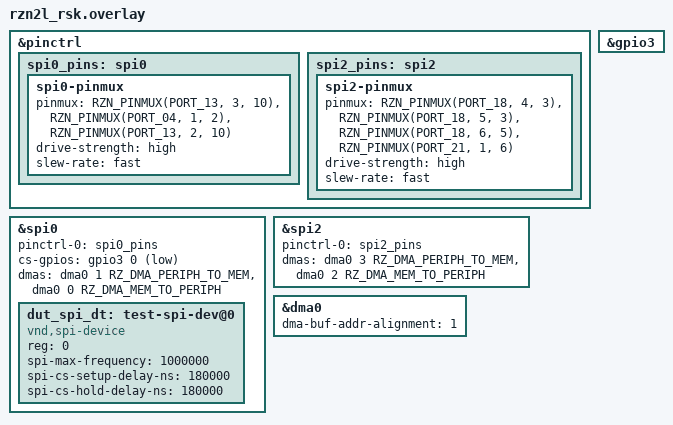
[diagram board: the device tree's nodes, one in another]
/*
 * Copyright (c) 2025 Renesas Electronics Corporation
 * SPDX-License-Identifier: Apache-2.0
 */

&pinctrl {
	/omit-if-no-ref/ spi0_pins: spi0 {
		spi0-pinmux {
			pinmux = <RZN_PINMUX(PORT_13, 3, 10)>, /* CK0 */
				 <RZN_PINMUX(PORT_04, 1, 2)>, /* MOSI0 */
				 <RZN_PINMUX(PORT_13, 2, 10)>; /* MISO0 */
			drive-strength = "high";
			slew-rate = "fast";
		};
	};

	/omit-if-no-ref/ spi2_pins: spi2 {
		spi2-pinmux {
			pinmux = <RZN_PINMUX(PORT_18, 4, 3)>, /* CK2 */
				 <RZN_PINMUX(PORT_18, 5, 3)>, /* MOSI2 */
				 <RZN_PINMUX(PORT_18, 6, 5)>, /* MISO2 */
				 <RZN_PINMUX(PORT_21, 1, 6)>; /* SSL20 */
			drive-strength = "high";
			slew-rate = "fast";
		};
	};
};

&gpio3 {
	status = "okay";
};

&spi0 {
	status = "okay";
	pinctrl-0 = <&spi0_pins>;
	pinctrl-names = "default";
	cs-gpios = <&gpio3 0 GPIO_ACTIVE_LOW>;

	dmas = <&dma0 1 RZ_DMA_PERIPH_TO_MEM>,
	       <&dma0 0 RZ_DMA_MEM_TO_PERIPH>;
	dma-names = "rx", "tx";

	dut_spi_dt: test-spi-dev@0 {
		compatible = "vnd,spi-device";
		reg = <0>;
		spi-max-frequency = <1000000>;
		spi-cs-setup-delay-ns = <180000>;
		spi-cs-hold-delay-ns = <180000>;
	};
};

dut_spis: &spi2 {
	status = "okay";
	pinctrl-0 = <&spi2_pins>;
	pinctrl-names = "default";

	dmas = <&dma0 3 RZ_DMA_PERIPH_TO_MEM>,
	       <&dma0 2 RZ_DMA_MEM_TO_PERIPH>;
	dma-names = "rx", "tx";
};

&dma0 {
	status = "okay";
	dma-buf-addr-alignment = <1>;
};
